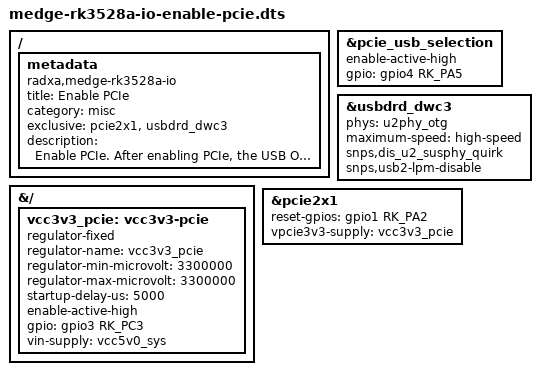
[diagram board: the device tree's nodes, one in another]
/dts-v1/;
/plugin/;

#include <dt-bindings/gpio/gpio.h>
#include <dt-bindings/pinctrl/rockchip.h>

/ {
	metadata {
		title = "Enable PCIe";
		compatible = "radxa,medge-rk3528a-io";
		category = "misc";
		exclusive = "pcie2x1", "usbdrd_dwc3";
		description = "Enable PCIe.
After enabling PCIe, the USB OTG port is limited to USB 2.0 speed.";
	};
};

&{/} {
	vcc3v3_pcie: vcc3v3-pcie {
		compatible = "regulator-fixed";
		regulator-name = "vcc3v3_pcie";
		regulator-min-microvolt = <3300000>;
		regulator-max-microvolt = <3300000>;
		startup-delay-us = <5000>;
		enable-active-high;
		gpio = <&gpio3 RK_PC3 GPIO_ACTIVE_HIGH>;
		vin-supply = <&vcc5v0_sys>;
	};
};

&pcie_usb_selection {
	enable-active-high;
	gpio = <&gpio4 RK_PA5 GPIO_ACTIVE_HIGH>;
};

&usbdrd_dwc3 {
	phys = <&u2phy_otg>;
	phy-names = "usb2-phy";
	maximum-speed = "high-speed";
	snps,dis_u2_susphy_quirk;
	snps,usb2-lpm-disable;
};

&pcie2x1 {
	reset-gpios = <&gpio1 RK_PA2 GPIO_ACTIVE_HIGH>;
	vpcie3v3-supply = <&vcc3v3_pcie>;
	status = "okay";
};
